# MSPM0G350X register map
Vendor: Texas Instruments; File version: This preliminary header file does not have a version number - build date: 2023-02-21 16:25:48
CPU: CM0 r0p1, little endian, MPU, no FPU, 3 interrupt priority bits
Registers are 32-bit, read-write, reset 0x0 unless marked. A register's access mark holds for its fields unless they carry their own. Offsets are from the block's base; [hi:lo] are bit positions.

## OPA0 — PERIPHERALREGION
Base 0x40020000
Same registers: OPA1 0x40022000
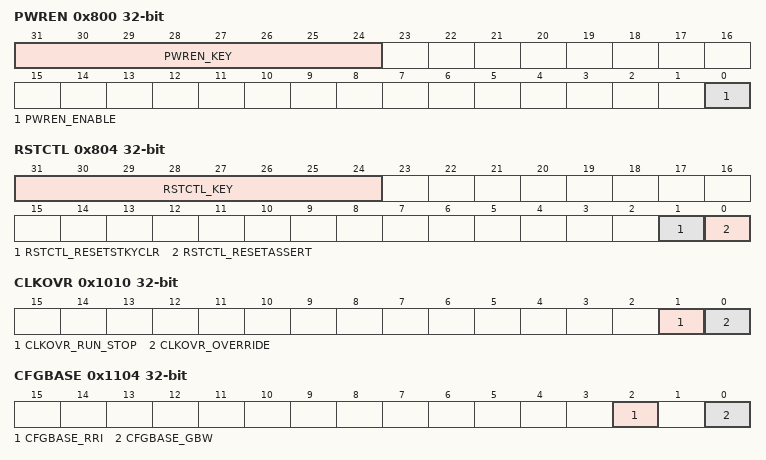
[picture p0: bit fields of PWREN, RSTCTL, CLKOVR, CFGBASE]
0x800 PWREN — Power enable
  [31:24] PWREN_KEY wo — KEY to allow Power State Change
    38=PWREN_KEY_UNLOCK_W (_TO_UNLOCK_W_)
  [0] PWREN_ENABLE — Enable the power
    0=PWREN_ENABLE_DISABLE (DISABLE); 1=PWREN_ENABLE_ENABLE (ENABLE)
0x804 RSTCTL wo — Reset Control
  [31:24] RSTCTL_KEY — Unlock key
    177=RSTCTL_KEY_UNLOCK_W (_TO_UNLOCK_W_)
  [1] RSTCTL_RESETSTKYCLR — Clear the RESETSTKY bit in the STAT register
    0=RSTCTL_RESETSTKYCLR_NOP (NOP); 1=RSTCTL_RESETSTKYCLR_CLR (CLR)
  [0] RSTCTL_RESETASSERT — Assert reset to the peripheral
    0=RSTCTL_RESETASSERT_NOP (NOP); 1=RSTCTL_RESETASSERT_ASSERT (ASSERT)
0x814 GPRCM_STAT ro — Status Register
  [16] GPRCM_STAT_RESETSTKY — This bit indicates, if the peripheral was reset, since this bit was cleared by RESETSTKYCLR in the RSTCTL register
    0=GPRCM_STAT_RESETSTKY_NORES (NORES); 1=GPRCM_STAT_RESETSTKY_RESET (RESET)
0x1010 CLKOVR — Clock Override
  [1] CLKOVR_RUN_STOP — If [OVERRIDE] is enabled, this register is used to manually control the peripheral's clock request to the system
    0=CLKOVR_RUN_STOP_RUN (RUN); 1=CLKOVR_RUN_STOP_STOP (STOP)
  [0] CLKOVR_OVERRIDE — Unlocks the functionality of [RUN_STOP] to override the automatic peripheral clock request
    0=CLKOVR_OVERRIDE_DISABLED (DISABLED); 1=CLKOVR_OVERRIDE_ENABLED (ENABLED)
0x101C PWRCTL — Power Control
  [0] PWRCTL_AUTO_OFF — When set the peripheral will remove its local IP request for enable so that it can be disabled if no other entities in the system are requesting it to be enabled.
    0=PWRCTL_AUTO_OFF_DISABLE (DISABLE); 1=PWRCTL_AUTO_OFF_ENABLE (ENABLE)
0x1100 CTL — Control Register
  [0] CTL_ENABLE — OAxn Enable.
    0=CTL_ENABLE_OFF (OFF); 1=CTL_ENABLE_ON (ON)
0x1104 CFGBASE — Configuration Base Register
  [2] CFGBASE_RRI — Rail-to-rail input enable. Can only be modified when STAT.BUSY=0
    0=CFGBASE_RRI_OFF (OFF); 1=CFGBASE_RRI_ON (ON)
  [0] CFGBASE_GBW — Select gain bandwidth which affects current as well the gain bandwidth. The lower gain bandwidth has lower current. See device specific datasheet for values. Can only be modified when STAT.BUSY=0.
    0=CFGBASE_GBW_LOWGAIN (LOWGAIN); 1=CFGBASE_GBW_HIGHGAIN (HIGHGAIN)
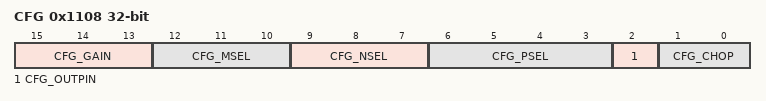
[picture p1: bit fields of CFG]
0x1108 CFG — Configuration Register
  [15:13] CFG_GAIN — Gain setting. Refer to TRM for enumeration information.
  [12:10] CFG_MSEL — MSEL Mux selection. Please refer to the device specific datasheet for exact channels available.
    0=CFG_MSEL_NC (NC); 1=CFG_MSEL_EXTNPIN1 (EXTNPIN1); 2=CFG_MSEL_VSS (VSS); 3=CFG_MSEL_DAC12OUT (DAC12OUT); 4=CFG_MSEL_OANM1RTOP (OANM1RTOP)
  [9:7] CFG_NSEL — Negative OA input selection. Please refer to the device specific datasheet for exact channels available.
    0=CFG_NSEL_NC (NC); 1=CFG_NSEL_EXTPIN0 (EXTPIN0); 2=CFG_NSEL_EXTPIN1 (EXTPIN1); 3=CFG_NSEL_OANP1RBOT (OANP1RBOT); 4=CFG_NSEL_OANRTAP (OANRTAP); 5=CFG_NSEL_OANRTOP (OANRTOP); 6=CFG_NSEL_SPARE (SPARE)
  [6:3] CFG_PSEL — Positive OA input selection. Please refer to the device specific datasheet for exact channels available.
    0=CFG_PSEL_NC (NC); 1=CFG_PSEL_EXTPIN0 (EXTPIN0); 2=CFG_PSEL_EXTPIN1 (EXTPIN1); 3=CFG_PSEL_DAC12OUT (DAC12OUT); 4=CFG_PSEL_DAC8OUT (DAC8OUT); 5=CFG_PSEL_VREF (VREF); 6=CFG_PSEL_OANM1RTOP (OANM1RTOP); 7=CFG_PSEL_GPAMP_OUT_INT (GPAMP_OUT_INT); 8=CFG_PSEL_VSS (VSS)
  [2] CFG_OUTPIN — Enable output pin
    0=CFG_OUTPIN_DISABLED (DISABLED); 1=CFG_OUTPIN_ENABLED (ENABLED)
  [1:0] CFG_CHOP — Chopping enable.
    0=CFG_CHOP_OFF (OFF); 1=CFG_CHOP_ON (ON); 2=CFG_CHOP_AVGON (AVGON)
0x1118 STAT ro — Status Register
  [0] STAT_RDY — OA ready status.
    0=STAT_RDY_FALSE (FALSE); 1=STAT_RDY_TRUE (TRUE)
